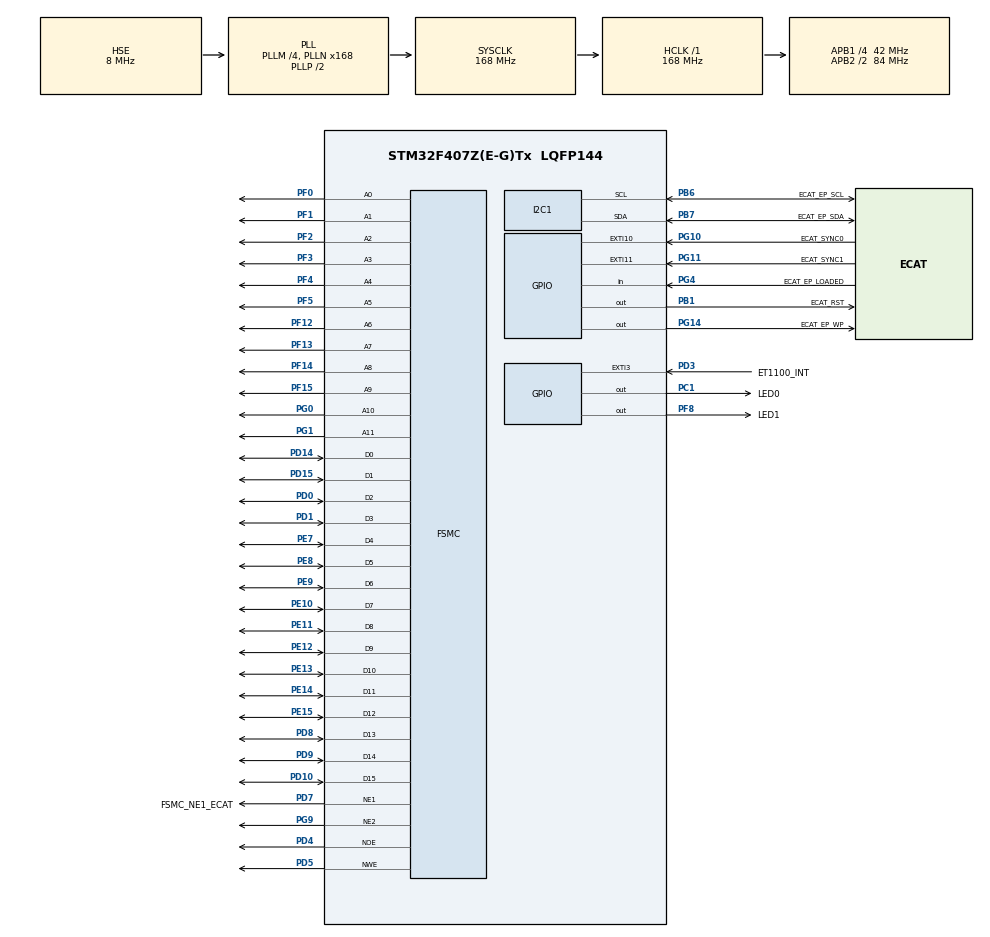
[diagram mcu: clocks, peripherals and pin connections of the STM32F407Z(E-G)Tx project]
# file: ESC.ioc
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FSMC.AddressSetupTime1=10
FSMC.BusTurnAroundDuration1=0
FSMC.BusTurnAroundDuration2=0
FSMC.DataSetupTime1=62
FSMC.DataSetupTime2=40
FSMC.ExtendedAddressSetupTime1=10
FSMC.ExtendedBusTurnAroundDuration1=0
FSMC.ExtendedBusTurnAroundDuration2=0
FSMC.ExtendedDataSetupTime1=62
FSMC.ExtendedDataSetupTime2=40
FSMC.ExtendedMode1=FSMC_EXTENDED_MODE_ENABLE
FSMC.ExtendedMode2=FSMC_EXTENDED_MODE_ENABLE
FSMC.WriteOperation1=FSMC_WRITE_OPERATION_ENABLE
FSMC.WriteOperation2=FSMC_WRITE_OPERATION_ENABLE
Mcu.Family=STM32F4
Mcu.Name=STM32F407Z(E-G)Tx
Mcu.Package=LQFP144
NVIC.EXTI15_10_IRQn=true\:0\:0\:false\:false\:true\:true\:true\:true
NVIC.EXTI3_IRQn=true\:0\:0\:false\:false\:true\:true\:true\:true
NVIC.PriorityGroup=NVIC_PRIORITYGROUP_4
PA13.Mode=Serial_Wire
PA13.Signal=SYS_JTMS-SWDIO
PA14.Mode=Serial_Wire
PA14.Signal=SYS_JTCK-SWCLK
PB1.GPIO_Label=ECAT_RST
PB1.GPIO_Speed=GPIO_SPEED_FREQ_VERY_HIGH
PB1.Signal=GPIO_Output
PB6.GPIO_Label=ECAT_EP_SCL
PB6.Mode=I2C
PB6.Signal=I2C1_SCL
PB7.GPIO_Label=ECAT_EP_SDA
PB7.Mode=I2C
PB7.Signal=I2C1_SDA
PC1.GPIO_Label=LED0
PC1.GPIO_PuPd=GPIO_PULLUP
PC1.GPIO_Speed=GPIO_SPEED_FREQ_VERY_HIGH
PC1.Signal=GPIO_Output
PD0.GPIO_Speed_High_Default=GPIO_SPEED_FREQ_VERY_HIGH
PD0.Signal=FSMC_D2_DA2
PD1.GPIO_Speed_High_Default=GPIO_SPEED_FREQ_VERY_HIGH
PD1.Signal=FSMC_D3_DA3
PD10.GPIO_Speed_High_Default=GPIO_SPEED_FREQ_VERY_HIGH
PD10.Signal=FSMC_D15_DA15
PD14.GPIO_Speed_High_Default=GPIO_SPEED_FREQ_VERY_HIGH
PD14.Signal=FSMC_D0_DA0
PD15.GPIO_Speed_High_Default=GPIO_SPEED_FREQ_VERY_HIGH
PD15.Signal=FSMC_D1_DA1
PD3.GPIO_Label=ET1100_INT
PD3.GPIO_PuPd=GPIO_PULLDOWN
PD3.Signal=GPXTI3
PD4.GPIO_Speed_High_Default=GPIO_SPEED_FREQ_VERY_HIGH
PD4.Signal=FSMC_NOE
PD5.GPIO_Speed_High_Default=GPIO_SPEED_FREQ_VERY_HIGH
PD5.Signal=FSMC_NWE
PD7.GPIO_Label=FSMC_NE1_ECAT
PD7.GPIO_Speed_High_Default=GPIO_SPEED_FREQ_VERY_HIGH
PD7.Mode=NorPsramChipSelect1_1
PD7.Signal=FSMC_NE1
PD8.GPIO_Speed_High_Default=GPIO_SPEED_FREQ_VERY_HIGH
PD8.Signal=FSMC_D13_DA13
PD9.GPIO_Speed_High_Default=GPIO_SPEED_FREQ_VERY_HIGH
PD9.Signal=FSMC_D14_DA14
PE10.GPIO_Speed_High_Default=GPIO_SPEED_FREQ_VERY_HIGH
PE10.Signal=FSMC_D7_DA7
PE11.GPIO_Speed_High_Default=GPIO_SPEED_FREQ_VERY_HIGH
PE11.Signal=FSMC_D8_DA8
PE12.GPIO_Speed_High_Default=GPIO_SPEED_FREQ_VERY_HIGH
PE12.Signal=FSMC_D9_DA9
PE13.GPIO_Speed_High_Default=GPIO_SPEED_FREQ_VERY_HIGH
PE13.Signal=FSMC_D10_DA10
PE14.GPIO_Speed_High_Default=GPIO_SPEED_FREQ_VERY_HIGH
PE14.Signal=FSMC_D11_DA11
PE15.GPIO_Speed_High_Default=GPIO_SPEED_FREQ_VERY_HIGH
PE15.Signal=FSMC_D12_DA12
PE7.GPIO_Speed_High_Default=GPIO_SPEED_FREQ_VERY_HIGH
PE7.Signal=FSMC_D4_DA4
PE8.GPIO_Speed_High_Default=GPIO_SPEED_FREQ_VERY_HIGH
PE8.Signal=FSMC_D5_DA5
PE9.GPIO_Speed_High_Default=GPIO_SPEED_FREQ_VERY_HIGH
PE9.Signal=FSMC_D6_DA6
PF0.GPIO_Speed_High_Default=GPIO_SPEED_FREQ_VERY_HIGH
PF0.Signal=FSMC_A0
PF1.GPIO_Speed_High_Default=GPIO_SPEED_FREQ_VERY_HIGH
PF1.Signal=FSMC_A1
PF12.GPIO_Speed_High_Default=GPIO_SPEED_FREQ_VERY_HIGH
PF12.Signal=FSMC_A6
PF13.GPIO_Speed_High_Default=GPIO_SPEED_FREQ_VERY_HIGH
PF13.Signal=FSMC_A7
PF14.GPIO_Speed_High_Default=GPIO_SPEED_FREQ_VERY_HIGH
PF14.Signal=FSMC_A8
PF15.GPIO_Speed_High_Default=GPIO_SPEED_FREQ_VERY_HIGH
PF15.Signal=FSMC_A9
PF2.GPIO_Speed_High_Default=GPIO_SPEED_FREQ_VERY_HIGH
PF2.Signal=FSMC_A2
PF3.GPIO_Speed_High_Default=GPIO_SPEED_FREQ_VERY_HIGH
PF3.Signal=FSMC_A3
PF4.GPIO_Speed_High_Default=GPIO_SPEED_FREQ_VERY_HIGH
PF4.Signal=FSMC_A4
PF5.GPIO_Speed_High_Default=GPIO_SPEED_FREQ_VERY_HIGH
PF5.Signal=FSMC_A5
PF8.GPIO_Label=LED1
PF8.GPIO_PuPd=GPIO_PULLUP
PF8.GPIO_Speed=GPIO_SPEED_FREQ_HIGH
PF8.Signal=GPIO_Output
PG0.GPIO_Speed_High_Default=GPIO_SPEED_FREQ_VERY_HIGH
PG0.Signal=FSMC_A10
PG1.GPIO_Speed_High_Default=GPIO_SPEED_FREQ_VERY_HIGH
PG1.Signal=FSMC_A11
PG10.GPIO_Label=ECAT_SYNC0
PG10.Signal=GPXTI10
PG11.GPIO_Label=ECAT_SYNC1
PG11.Signal=GPXTI11
PG14.GPIO_Label=ECAT_EP_WP
PG14.GPIO_Speed=GPIO_SPEED_FREQ_VERY_HIGH
PG14.Signal=GPIO_Output
PG4.GPIO_Label=ECAT_EP_LOADED
PG4.GPIO_PuPd=GPIO_NOPULL
PG4.Signal=GPIO_Input
PG9.Mode=NorPsramChipSelect2_2
PG9.Signal=FSMC_NE2
PH0-OSC_IN.Mode=HSE-External-Oscillator
PH0-OSC_IN.Signal=RCC_OSC_IN
PH1-OSC_OUT.Mode=HSE-External-Oscillator
PH1-OSC_OUT.Signal=RCC_OSC_OUT
ProjectManager.HeapSize=0x2000
ProjectManager.StackSize=0x4000
ProjectManager.TargetToolchain=MDK-ARM V5
RCC.48MHZClocksFreq_Value=84000000
RCC.AHBFreq_Value=168000000
RCC.APB1CLKDivider=RCC_HCLK_DIV4
RCC.APB1Freq_Value=42000000
RCC.APB1TimFreq_Value=84000000
RCC.APB2CLKDivider=RCC_HCLK_DIV2
RCC.APB2Freq_Value=84000000
RCC.APB2TimFreq_Value=168000000
RCC.CortexFreq_Value=168000000
RCC.HCLKFreq_Value=168000000
RCC.HSE_VALUE=8000000
RCC.HSI_VALUE=16000000
RCC.LSE_VALUE=32768
RCC.PLLM=4
RCC.PLLN=168
RCC.PLLSourceVirtual=RCC_PLLSOURCE_HSE
RCC.SYSCLKFreq_VALUE=168000000
RCC.SYSCLKSource=RCC_SYSCLKSOURCE_PLLCLK
RCC.VCOOutputFreq_Value=336000000
SH.FSMC_A0.0=FSMC_A0,12b-a1
SH.FSMC_A0.1=FSMC_A0,12b-a2
SH.FSMC_A1.0=FSMC_A1,12b-a1
SH.FSMC_A1.1=FSMC_A1,12b-a2
SH.FSMC_A10.0=FSMC_A10,12b-a1
SH.FSMC_A10.1=FSMC_A10,12b-a2
SH.FSMC_A11.0=FSMC_A11,12b-a1
SH.FSMC_A11.1=FSMC_A11,12b-a2
SH.FSMC_A2.0=FSMC_A2,12b-a1
SH.FSMC_A2.1=FSMC_A2,12b-a2
SH.FSMC_A3.0=FSMC_A3,12b-a1
SH.FSMC_A3.1=FSMC_A3,12b-a2
SH.FSMC_A4.0=FSMC_A4,12b-a1
SH.FSMC_A4.1=FSMC_A4,12b-a2
SH.FSMC_A5.0=FSMC_A5,12b-a1
SH.FSMC_A5.1=FSMC_A5,12b-a2
SH.FSMC_A6.0=FSMC_A6,12b-a1
SH.FSMC_A6.1=FSMC_A6,12b-a2
SH.FSMC_A7.0=FSMC_A7,12b-a1
SH.FSMC_A7.1=FSMC_A7,12b-a2
SH.FSMC_A8.0=FSMC_A8,12b-a1
SH.FSMC_A8.1=FSMC_A8,12b-a2
SH.FSMC_A9.0=FSMC_A9,12b-a1
SH.FSMC_A9.1=FSMC_A9,12b-a2
SH.FSMC_D0_DA0.0=FSMC_D0,16b-d1
SH.FSMC_D0_DA0.1=FSMC_D0,16b-d2
SH.FSMC_D10_DA10.0=FSMC_D10,16b-d1
SH.FSMC_D10_DA10.1=FSMC_D10,16b-d2
SH.FSMC_D11_DA11.0=FSMC_D11,16b-d1
SH.FSMC_D11_DA11.1=FSMC_D11,16b-d2
SH.FSMC_D12_DA12.0=FSMC_D12,16b-d1
SH.FSMC_D12_DA12.1=FSMC_D12,16b-d2
SH.FSMC_D13_DA13.0=FSMC_D13,16b-d1
SH.FSMC_D13_DA13.1=FSMC_D13,16b-d2
SH.FSMC_D14_DA14.0=FSMC_D14,16b-d1
SH.FSMC_D14_DA14.1=FSMC_D14,16b-d2
SH.FSMC_D15_DA15.0=FSMC_D15,16b-d1
SH.FSMC_D15_DA15.1=FSMC_D15,16b-d2
SH.FSMC_D1_DA1.0=FSMC_D1,16b-d1
SH.FSMC_D1_DA1.1=FSMC_D1,16b-d2
SH.FSMC_D2_DA2.0=FSMC_D2,16b-d1
SH.FSMC_D2_DA2.1=FSMC_D2,16b-d2
SH.FSMC_D3_DA3.0=FSMC_D3,16b-d1
SH.FSMC_D3_DA3.1=FSMC_D3,16b-d2
SH.FSMC_D4_DA4.0=FSMC_D4,16b-d1
SH.FSMC_D4_DA4.1=FSMC_D4,16b-d2
SH.FSMC_D5_DA5.0=FSMC_D5,16b-d1
SH.FSMC_D5_DA5.1=FSMC_D5,16b-d2
SH.FSMC_D6_DA6.0=FSMC_D6,16b-d1
SH.FSMC_D6_DA6.1=FSMC_D6,16b-d2
SH.FSMC_D7_DA7.0=FSMC_D7,16b-d1
SH.FSMC_D7_DA7.1=FSMC_D7,16b-d2
SH.FSMC_D8_DA8.0=FSMC_D8,16b-d1
SH.FSMC_D8_DA8.1=FSMC_D8,16b-d2
SH.FSMC_D9_DA9.0=FSMC_D9,16b-d1
SH.FSMC_D9_DA9.1=FSMC_D9,16b-d2
SH.FSMC_NOE.0=FSMC_NOE,Sram1
SH.FSMC_NOE.1=FSMC_NOE,Sram2
SH.FSMC_NWE.0=FSMC_NWE,Sram1
SH.FSMC_NWE.1=FSMC_NWE,Sram2
board=custom

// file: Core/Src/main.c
/* USER CODE BEGIN Header */
/**
  ******************************************************************************
  * @file           : main.c
  * @brief          : Main program body
  ******************************************************************************
  * @attention
  *
  * Copyright (c) 2025 STMicroelectronics.
  * All rights reserved.
  *
  * This software is licensed under terms that can be found in the LICENSE file
  * in the root directory of this software component.
  * If no LICENSE file comes with this software, it is provided AS-IS.
  *
  ******************************************************************************
  */
/* USER CODE END Header */
#include "main.h"

/* USER CODE BEGIN Includes */
#include "ecat_def.h"
/* USER CODE END Includes */

I2C_HandleTypeDef hi2c1;

SRAM_HandleTypeDef hsram1;
SRAM_HandleTypeDef hsram2;

void SystemClock_Config(void);
static void MX_GPIO_Init(void);
static void MX_FSMC_Init(void);
static void MX_I2C1_Init(void);
/* USER CODE BEGIN PFP */
extern void HW_Init(void);
extern void MainInit(void);
extern void MainLoop(void);
/* USER CODE END PFP */

int main(void)
{

  /* MCU Configuration--------------------------------------------------------*/

  /* Reset of all peripherals, Initializes the Flash interface and the Systick. */
  HAL_Init();

  /* Configure the system clock */
  SystemClock_Config();

  /* Initialize all configured peripherals */
  MX_GPIO_Init();
  MX_FSMC_Init();
  MX_I2C1_Init();
  /* USER CODE BEGIN 2 */

	HW_Init();
	MainInit();
  /* USER CODE END 2 */

  /* Infinite loop */
  /* USER CODE BEGIN WHILE */
  while (1)
  {
		MainLoop();
    /* USER CODE END WHILE */
  }
}

void SystemClock_Config(void)
{
  RCC_OscInitTypeDef RCC_OscInitStruct = {0};
  RCC_ClkInitTypeDef RCC_ClkInitStruct = {0};

  /** Configure the main internal regulator output voltage
  */
  __HAL_RCC_PWR_CLK_ENABLE();
  __HAL_PWR_VOLTAGESCALING_CONFIG(PWR_REGULATOR_VOLTAGE_SCALE1);

  /** Initializes the RCC Oscillators according to the specified parameters
  * in the RCC_OscInitTypeDef structure.
  */
  RCC_OscInitStruct.OscillatorType = RCC_OSCILLATORTYPE_HSE;
  RCC_OscInitStruct.HSEState = RCC_HSE_ON;
  RCC_OscInitStruct.PLL.PLLState = RCC_PLL_ON;
  RCC_OscInitStruct.PLL.PLLSource = RCC_PLLSOURCE_HSE;
  RCC_OscInitStruct.PLL.PLLM = 4;
  RCC_OscInitStruct.PLL.PLLN = 168;
  RCC_OscInitStruct.PLL.PLLP = RCC_PLLP_DIV2;
  RCC_OscInitStruct.PLL.PLLQ = 4;
  if (HAL_RCC_OscConfig(&RCC_OscInitStruct) != HAL_OK)
  {
    Error_Handler();
  }

  /** Initializes the CPU, AHB and APB buses clocks
  */
  RCC_ClkInitStruct.ClockType = RCC_CLOCKTYPE_HCLK|RCC_CLOCKTYPE_SYSCLK
                              |RCC_CLOCKTYPE_PCLK1|RCC_CLOCKTYPE_PCLK2;
  RCC_ClkInitStruct.SYSCLKSource = RCC_SYSCLKSOURCE_PLLCLK;
  RCC_ClkInitStruct.AHBCLKDivider = RCC_SYSCLK_DIV1;
  RCC_ClkInitStruct.APB1CLKDivider = RCC_HCLK_DIV4;
  RCC_ClkInitStruct.APB2CLKDivider = RCC_HCLK_DIV2;

  if (HAL_RCC_ClockConfig(&RCC_ClkInitStruct, FLASH_LATENCY_5) != HAL_OK)
  {
    Error_Handler();
  }
}

static void MX_I2C1_Init(void)
{

  hi2c1.Instance = I2C1;
  hi2c1.Init.ClockSpeed = 100000;
  hi2c1.Init.DutyCycle = I2C_DUTYCYCLE_2;
  hi2c1.Init.OwnAddress1 = 0;
  hi2c1.Init.AddressingMode = I2C_ADDRESSINGMODE_7BIT;
  hi2c1.Init.DualAddressMode = I2C_DUALADDRESS_DISABLE;
  hi2c1.Init.OwnAddress2 = 0;
  hi2c1.Init.GeneralCallMode = I2C_GENERALCALL_DISABLE;
  hi2c1.Init.NoStretchMode = I2C_NOSTRETCH_DISABLE;
  if (HAL_I2C_Init(&hi2c1) != HAL_OK)
  {
    Error_Handler();
  }

}

static void MX_GPIO_Init(void)
{
  GPIO_InitTypeDef GPIO_InitStruct = {0};

  /* GPIO Ports Clock Enable */
  __HAL_RCC_GPIOF_CLK_ENABLE();
  __HAL_RCC_GPIOH_CLK_ENABLE();
  __HAL_RCC_GPIOC_CLK_ENABLE();
  __HAL_RCC_GPIOB_CLK_ENABLE();
  __HAL_RCC_GPIOG_CLK_ENABLE();
  __HAL_RCC_GPIOE_CLK_ENABLE();
  __HAL_RCC_GPIOD_CLK_ENABLE();
  __HAL_RCC_GPIOA_CLK_ENABLE();

  /*Configure GPIO pin Output Level */
  HAL_GPIO_WritePin(LED1_GPIO_Port, LED1_Pin, GPIO_PIN_RESET);

  /*Configure GPIO pin Output Level */
  HAL_GPIO_WritePin(LED0_GPIO_Port, LED0_Pin, GPIO_PIN_RESET);

  /*Configure GPIO pin Output Level */
  HAL_GPIO_WritePin(ECAT_RST_GPIO_Port, ECAT_RST_Pin, GPIO_PIN_RESET);

  /*Configure GPIO pin Output Level */
  HAL_GPIO_WritePin(ECAT_EP_WP_GPIO_Port, ECAT_EP_WP_Pin, GPIO_PIN_RESET);

  /*Configure GPIO pin : LED1_Pin */
  GPIO_InitStruct.Pin = LED1_Pin;
  GPIO_InitStruct.Mode = GPIO_MODE_OUTPUT_PP;
  GPIO_InitStruct.Pull = GPIO_PULLUP;
  GPIO_InitStruct.Speed = GPIO_SPEED_FREQ_HIGH;
  HAL_GPIO_Init(LED1_GPIO_Port, &GPIO_InitStruct);

  /*Configure GPIO pin : LED0_Pin */
  GPIO_InitStruct.Pin = LED0_Pin;
  GPIO_InitStruct.Mode = GPIO_MODE_OUTPUT_PP;
  GPIO_InitStruct.Pull = GPIO_PULLUP;
  GPIO_InitStruct.Speed = GPIO_SPEED_FREQ_VERY_HIGH;
  HAL_GPIO_Init(LED0_GPIO_Port, &GPIO_InitStruct);

  /*Configure GPIO pin : ECAT_RST_Pin */
  GPIO_InitStruct.Pin = ECAT_RST_Pin;
  GPIO_InitStruct.Mode = GPIO_MODE_OUTPUT_PP;
  GPIO_InitStruct.Pull = GPIO_NOPULL;
  GPIO_InitStruct.Speed = GPIO_SPEED_FREQ_VERY_HIGH;
  HAL_GPIO_Init(ECAT_RST_GPIO_Port, &GPIO_InitStruct);

  /*Configure GPIO pin : ECAT_EP_LOADED_Pin */
  GPIO_InitStruct.Pin = ECAT_EP_LOADED_Pin;
  GPIO_InitStruct.Mode = GPIO_MODE_INPUT;
  GPIO_InitStruct.Pull = GPIO_NOPULL;
  HAL_GPIO_Init(ECAT_EP_LOADED_GPIO_Port, &GPIO_InitStruct);

  /*Configure GPIO pin : ET1100_INT_Pin */
  GPIO_InitStruct.Pin = ET1100_INT_Pin;
  GPIO_InitStruct.Mode = GPIO_MODE_IT_RISING;
  GPIO_InitStruct.Pull = GPIO_PULLDOWN;
  HAL_GPIO_Init(ET1100_INT_GPIO_Port, &GPIO_InitStruct);

  /*Configure GPIO pins : ECAT_SYNC0_Pin ECAT_SYNC1_Pin */
  GPIO_InitStruct.Pin = ECAT_SYNC0_Pin|ECAT_SYNC1_Pin;
  GPIO_InitStruct.Mode = GPIO_MODE_IT_RISING;
  GPIO_InitStruct.Pull = GPIO_NOPULL;
  HAL_GPIO_Init(GPIOG, &GPIO_InitStruct);

  /*Configure GPIO pin : ECAT_EP_WP_Pin */
  GPIO_InitStruct.Pin = ECAT_EP_WP_Pin;
  GPIO_InitStruct.Mode = GPIO_MODE_OUTPUT_PP;
  GPIO_InitStruct.Pull = GPIO_NOPULL;
  GPIO_InitStruct.Speed = GPIO_SPEED_FREQ_VERY_HIGH;
  HAL_GPIO_Init(ECAT_EP_WP_GPIO_Port, &GPIO_InitStruct);

  /* EXTI interrupt init*/
  HAL_NVIC_SetPriority(EXTI3_IRQn, 0, 0);
  // HAL_NVIC_EnableIRQ(EXTI3_IRQn);

  HAL_NVIC_SetPriority(EXTI15_10_IRQn, 0, 0);
   HAL_NVIC_EnableIRQ(EXTI15_10_IRQn);

}

/* FSMC initialization function */
static void MX_FSMC_Init(void)
{

  FSMC_NORSRAM_TimingTypeDef Timing = {0};
  FSMC_NORSRAM_TimingTypeDef ExtTiming = {0};

  /** Perform the SRAM1 memory initialization sequence
  */
  hsram1.Instance = FSMC_NORSRAM_DEVICE;
  hsram1.Extended = FSMC_NORSRAM_EXTENDED_DEVICE;
  /* hsram1.Init */
  hsram1.Init.NSBank = FSMC_NORSRAM_BANK1;
  hsram1.Init.DataAddressMux = FSMC_DATA_ADDRESS_MUX_DISABLE;
  hsram1.Init.MemoryType = FSMC_MEMORY_TYPE_SRAM;
  hsram1.Init.MemoryDataWidth = FSMC_NORSRAM_MEM_BUS_WIDTH_16;
  hsram1.Init.BurstAccessMode = FSMC_BURST_ACCESS_MODE_DISABLE;
  hsram1.Init.WaitSignalPolarity = FSMC_WAIT_SIGNAL_POLARITY_LOW;
  hsram1.Init.WrapMode = FSMC_WRAP_MODE_DISABLE;
  hsram1.Init.WaitSignalActive = FSMC_WAIT_TIMING_BEFORE_WS;
  hsram1.Init.WriteOperation = FSMC_WRITE_OPERATION_ENABLE;
  hsram1.Init.WaitSignal = FSMC_WAIT_SIGNAL_DISABLE;
  hsram1.Init.ExtendedMode = FSMC_EXTENDED_MODE_ENABLE;
  hsram1.Init.AsynchronousWait = FSMC_ASYNCHRONOUS_WAIT_DISABLE;
  hsram1.Init.WriteBurst = FSMC_WRITE_BURST_DISABLE;
  hsram1.Init.PageSize = FSMC_PAGE_SIZE_NONE;
  /* Timing */
  Timing.AddressSetupTime = 10;
  Timing.AddressHoldTime = 10;
  Timing.DataSetupTime = 100;
  Timing.BusTurnAroundDuration = 0;
  Timing.CLKDivision = 0;
  Timing.DataLatency = 0;
  Timing.AccessMode = FSMC_ACCESS_MODE_A;
  /* ExtTiming */
  ExtTiming.AddressSetupTime = 10;
  ExtTiming.AddressHoldTime = 10;
  ExtTiming.DataSetupTime = 100;
  ExtTiming.BusTurnAroundDuration = 0;
  ExtTiming.CLKDivision = 0;
  ExtTiming.DataLatency = 0;
  ExtTiming.AccessMode = FSMC_ACCESS_MODE_A;

  if (HAL_SRAM_Init(&hsram1, &Timing, &ExtTiming) != HAL_OK)
  {
    Error_Handler( );
  }

  /** Perform the SRAM2 memory initialization sequence
  */
  hsram2.Instance = FSMC_NORSRAM_DEVICE;
  hsram2.Extended = FSMC_NORSRAM_EXTENDED_DEVICE;
  /* hsram2.Init */
  hsram2.Init.NSBank = FSMC_NORSRAM_BANK2;
  hsram2.Init.DataAddressMux = FSMC_DATA_ADDRESS_MUX_DISABLE;
  hsram2.Init.MemoryType = FSMC_MEMORY_TYPE_SRAM;
  hsram2.Init.MemoryDataWidth = FSMC_NORSRAM_MEM_BUS_WIDTH_16;
  hsram2.Init.BurstAccessMode = FSMC_BURST_ACCESS_MODE_DISABLE;
  hsram2.Init.WaitSignalPolarity = FSMC_WAIT_SIGNAL_POLARITY_LOW;
  hsram2.Init.WrapMode = FSMC_WRAP_MODE_DISABLE;
  hsram2.Init.WaitSignalActive = FSMC_WAIT_TIMING_BEFORE_WS;
  hsram2.Init.WriteOperation = FSMC_WRITE_OPERATION_ENABLE;
  hsram2.Init.WaitSignal = FSMC_WAIT_SIGNAL_DISABLE;
  hsram2.Init.ExtendedMode = FSMC_EXTENDED_MODE_ENABLE;
  hsram2.Init.AsynchronousWait = FSMC_ASYNCHRONOUS_WAIT_DISABLE;
  hsram2.Init.WriteBurst = FSMC_WRITE_BURST_DISABLE;
  hsram2.Init.PageSize = FSMC_PAGE_SIZE_NONE;
  /* Timing */
  Timing.AddressSetupTime = 15;
  Timing.AddressHoldTime = 15;
  Timing.DataSetupTime = 80;
  Timing.BusTurnAroundDuration = 0;
  Timing.CLKDivision = 0;
  Timing.DataLatency = 0;
  Timing.AccessMode = FSMC_ACCESS_MODE_A;
  /* ExtTiming */
  ExtTiming.AddressSetupTime = 15;
  ExtTiming.AddressHoldTime = 15;
  ExtTiming.DataSetupTime = 80;
  ExtTiming.BusTurnAroundDuration = 0;
  ExtTiming.CLKDivision = 0;
  ExtTiming.DataLatency = 0;
  ExtTiming.AccessMode = FSMC_ACCESS_MODE_A;

  if (HAL_SRAM_Init(&hsram2, &Timing, &ExtTiming) != HAL_OK)
  {
    Error_Handler( );
  }

}

void Error_Handler(void)
{
  __disable_irq();
  while (1)
  {
  }
}
